# STM32N647 register map
File version: 1.0
CPU: CM55 r0p1, little endian, no MPU, FPU, vendor SysTick, 8 interrupt priority bits
Registers are 32-bit, read-write, reset 0x0 unless marked. A register's access mark holds for its fields unless they carry their own. Offsets are from the block's base; [hi:lo] are bit positions; {n}, {i} and the like mark numbered series.

## GPDMA — General purpose direct memory access controller
Base 0x40021000
Same registers: GPDMA_S 0x50021000
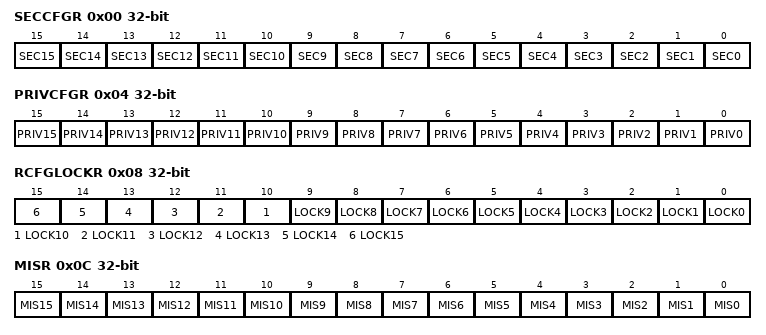
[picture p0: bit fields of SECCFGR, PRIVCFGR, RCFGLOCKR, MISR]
0x00 SECCFGR — GPDMA secure configuration register
  [n] SEC{n} (n=0..15) — secure state of channel x
0x04 PRIVCFGR — GPDMA privileged configuration register
  [n] PRIV{n} (n=0..15) — privileged state of channel x
0x08 RCFGLOCKR — GPDMA configuration lock register
  [n] LOCK{n} (n=0..15) — lock the configuration of GPDMA_SECCFGR.SECx and GPDMA_PRIVCFGR.PRIVx, until a global GPDMA reset
0x0C MISR ro — GPDMA non-secure masked interrupt status register
  [n] MIS{n} (n=0..15) — masked interrupt status of channel x
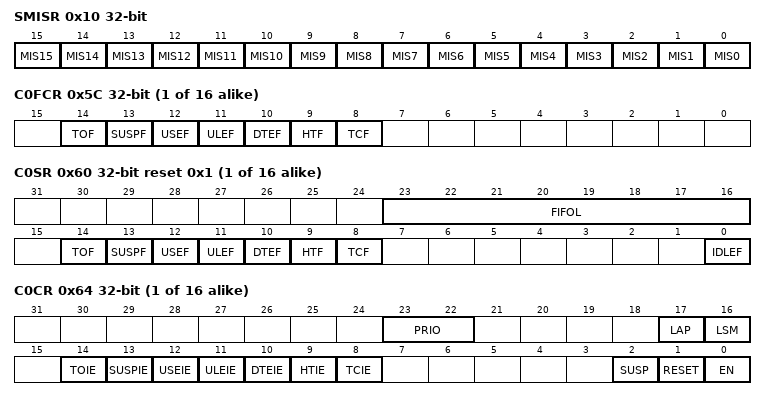
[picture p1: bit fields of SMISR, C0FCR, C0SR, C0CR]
0x10 SMISR ro — GPDMA secure masked interrupt status register
  [n] MIS{n} (n=0..15) — masked interrupt status of the secure channel x
{0x50+0x80*i} C{i}LBAR (i=0..15) — GPDMA channel {i} linked-list base address register
  [31:16] LBA — linked-list base address of GPDMA channel x
{0x5C+0x80*i} C{i}FCR wo (i=0..15) — GPDMA channel {i} flag clear register
  [14] TOF — trigger overrun flag clear
  [13] SUSPF — completed suspension flag clear
  [12] USEF — user setting error flag clear
  [11] ULEF — update link transfer error flag clear
  [10] DTEF — data transfer error flag clear
  [9] HTF — half transfer flag clear
  [8] TCF — transfer complete flag clear
{0x60+0x80*i} C{i}SR ro reset 0x1 (i=0..15) — GPDMA channel {i} status register
  [23:16] FIFOL — monitored FIFO level
  [14] TOF — trigger overrun flag
  [13] SUSPF — completed suspension flag
  [12] USEF — user setting error flag
  [11] ULEF — update link transfer error flag
  [10] DTEF — data transfer error flag
  [9] HTF — half transfer flag
  [8] TCF — transfer complete flag
  [0] IDLEF — idle flag
{0x64+0x80*i} C{i}CR access per field (i=0..15) — GPDMA channel {i} control register
  [23:22] PRIO rw — priority level of the channel x GPDMA transfer versus others
  [17] LAP rw — linked-list allocated port
  [16] LSM rw — Link step mode
  [14] TOIE rw — trigger overrun interrupt enable
  [13] SUSPIE rw — completed suspension interrupt enable
  [12] USEIE rw — user setting error interrupt enable
  [11] ULEIE rw — update link transfer error interrupt enable
  [10] DTEIE rw — data transfer error interrupt enable
  [9] HTIE rw — half transfer complete interrupt enable
  [8] TCIE rw — transfer complete interrupt enable
  [2] SUSP rw — suspend
  [1] RESET wo
  [0] EN rw — enable
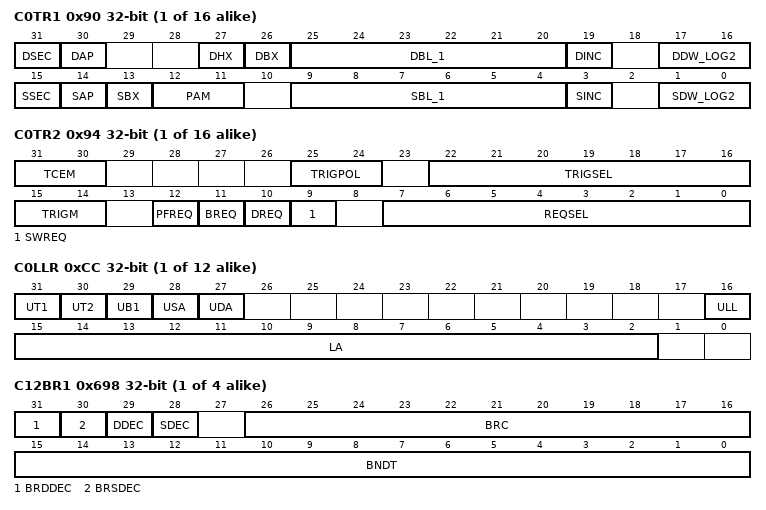
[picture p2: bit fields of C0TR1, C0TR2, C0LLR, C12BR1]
{0x90+0x80*i} C{i}TR1 (i=0..15) — GPDMA channel {i} transfer register 1
  [31] DSEC — security attribute of the GPDMA transfer to the destination
  [30] DAP — destination allocated port
  [27] DHX — destination half-word exchange
  [26] DBX — destination byte exchange
  [25:20] DBL_1 — destination burst length minus 1, between 0 and 63
  [19] DINC — destination incrementing burst
  [17:16] DDW_LOG2 — binary logarithm of the destination data width of a burst, in bytes
  [15] SSEC — security attribute of the GPDMA transfer from the source
  [14] SAP — source allocated port
  [13] SBX — source byte exchange within the unaligned half-word of each source word
  [12:11] PAM — padding/alignment mode
  [9:4] SBL_1 — source burst length minus 1, between 0 and 63
  [3] SINC — source incrementing burst
  [1:0] SDW_LOG2 — binary logarithm of the source data width of a burst in bytes
{0x94+0x80*i} C{i}TR2 (i=0..15) — GPDMA channel {i} transfer register 2
  [31:30] TCEM — transfer complete event mode
  [25:24] TRIGPOL — trigger event polarity
  [22:16] TRIGSEL — trigger event input selection
  [15:14] TRIGM — trigger mode
  [12] PFREQ — Hardware request in peripheral flow control mode
  [11] BREQ — Block hardware request
  [10] DREQ — destination hardware request
  [9] SWREQ — software request
  [7:0] REQSEL — GPDMA hardware request selection
{0x98+0x80*i} C{i}BR1 (i=0..11) — GPDMA channel {i} block register 1
  [15:0] BNDT — block number of data bytes to transfer from the source
{0x9C+0x80*i} C{i}SAR (i=0..15) — GPDMA channel {i} source address register
  [31:0] SA — source address
{0xA0+0x80*i} C{i}DAR (i=0..15) — GPDMA channel {i} destination address register
  [31:0] DA — destination address
{0xCC+0x80*i} C{i}LLR (i=0..11) — GPDMA channel {i} linked-list address register
  [31] UT1 — Update GPDMA_CxTR1 from memory
  [30] UT2 — Update GPDMA_CxTR2 from memory
  [29] UB1 — Update GPDMA_CxBR1 from memory
  [28] USA — update GPDMA_CxSAR from memory
  [27] UDA — Update GPDMA_CxDAR register from memory
  [16] ULL — Update GPDMA_CxLLR register from memory
  [15:2] LA — pointer (16-bit low-significant address) to the next linked-list data structure
{0x98+0x80*i} C{i}BR1 (i=12..15) — GPDMA channel {i} alternate block register 1
  [31] BRDDEC — Block repeat destination address decrement
  [30] BRSDEC — Block repeat source address decrement
  [29] DDEC — destination address decrement
  [28] SDEC — source address decrement
  [26:16] BRC — Block repeat counter
  [15:0] BNDT — block number of data bytes to transfer from the source
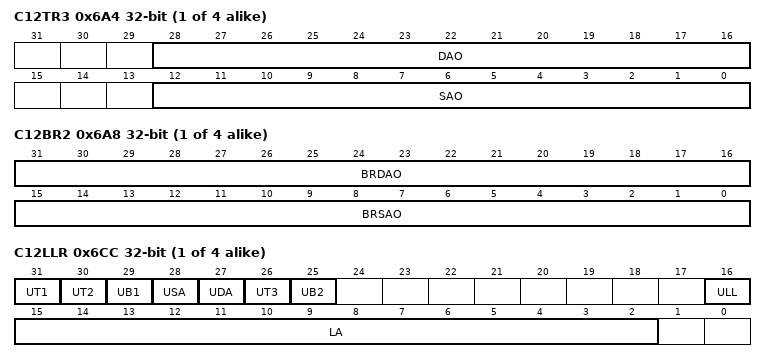
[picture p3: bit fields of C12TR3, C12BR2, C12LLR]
{0xA4+0x80*i} C{i}TR3 (i=12..15) — GPDMA channel {i} transfer register 3
  [28:16] DAO — destination address offset increment
  [12:0] SAO — source address offset increment
{0xA8+0x80*i} C{i}BR2 (i=12..15) — GPDMA channel {i} block register 2
  [31:16] BRDAO — Block repeated destination address offset
  [15:0] BRSAO — Block repeated source address offset
{0xCC+0x80*i} C{i}LLR (i=12..15) — GPDMA channel {i} alternate linked-list address register
  [31] UT1 — Update GPDMA_CxTR1 from memory
  [30] UT2 — Update GPDMA_CxTR2 from memory
  [29] UB1 — Update GPDMA_CxBR1 from memory
  [28] USA — update GPDMA_CxSAR from memory
  [27] UDA — Update GPDMA_CxDAR register from memory
  [26] UT3 — Update GPDMA_CxTR3 from memory
  [25] UB2 — Update GPDMA_CxBR2 from memory
  [16] ULL — Update GPDMA_CxLLR register from memory
  [15:2] LA — pointer (16-bit low-significant address) to the next linked-list data structure
